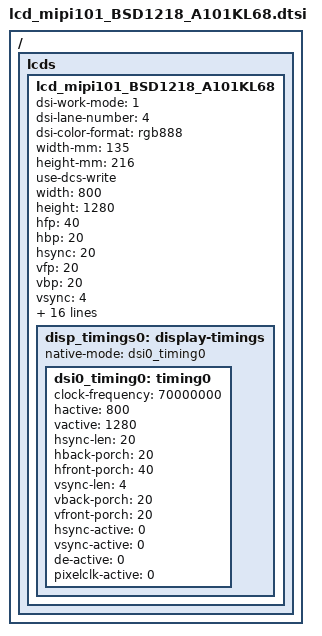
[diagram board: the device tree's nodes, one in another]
// SPDX-License-Identifier: GPL-2.0

/ {
	lcds: lcds  {
		lcd_mipi101_BSD1218_A101KL68: lcd_mipi101_BSD1218_A101KL68 {
			dsi-work-mode = <1>; /* video burst mode*/
			dsi-lane-number = <4>;
			dsi-color-format = "rgb888";
			width-mm = <135>;
			height-mm = <216>;
			use-dcs-write;

			/*mipi info*/
			width = <800>;
			height = <1280>;
			hfp = <40>;
			hbp = <20>;
			hsync = <20>;
			vfp = <20>;
			vbp = <20>;
			vsync = <4>;
			fps = <60>;
			work-mode = <0>;
			rgb-mode = <3>;
			lane-number = <4>;
			phy-freq = <550000>;
			phy-escape-clock = <52000>;/* kHz */
			phy-bit-clock = <550000000>; /* 550 MHz/lane, within the calculated range for 800x1280@60. */
			split-enable = <0>;
			eotp-enable = <0>;
			burst-mode = <2>;
			esd-check-enable = <0>;
			te-esd-en = <0>;

			/* DSI_CMD, DSI_MODE, timeout, len, cmd  */
			initial-command = [
				39 01 00 04 FF 98 81 03
				39 01 00 02 01 00
				39 01 00 02 02 00
				39 01 00 02 03 55
				39 01 00 02 04 55
				39 01 00 02 05 03 
				39 01 00 02 06 06 
				39 01 00 02 07 00 
				39 01 00 02 08 07 
				39 01 00 02 09 00 
				39 01 00 02 0a 00 
				39 01 00 02 0b 00 
				39 01 00 02 0c 00 
				39 01 00 02 0d 00 
				39 01 00 02 0e 00 
				39 01 00 02 0f 00 

				39 01 00 02 10 00 
				39 01 00 02 11 00 
				39 01 00 02 12 00
				39 01 00 02 13 00
				39 01 00 02 14 00
				39 01 00 02 15 00
				39 01 00 02 16 00
				39 01 00 02 17 00
				39 01 00 02 18 00
				39 01 00 02 19 00
				39 01 00 02 1a 00
				39 01 00 02 1b 00
				39 01 00 02 1c 00
				39 01 00 02 1d 00
				39 01 00 02 1e C0
				39 01 00 02 1f 80

				39 01 00 02 20 04
				39 01 00 02 21 03
				39 01 00 02 22 00
				39 01 00 02 23 00
                                39 01 00 02 24 00
				39 01 00 02 25 00
				39 01 00 02 26 00
				39 01 00 02 27 00
				39 01 00 02 28 33
				39 01 00 02 29 33
				39 01 00 02 2a 00
				39 01 00 02 2b 00
				39 01 00 02 2c 00
				39 01 00 02 2d 00
				39 01 00 02 2e 00
				39 01 00 02 2f 00

				39 01 00 02 30 00
				39 01 00 02 31 00
				39 01 00 02 32 00
				39 01 00 02 33 00
				39 01 00 02 34 04
				39 01 00 02 35 00
				39 01 00 02 36 00
				39 01 00 02 37 00
				39 01 00 02 38 3C
                                39 01 00 02 39 00
				39 01 00 02 3a 00
				39 01 00 02 3b 00
				39 01 00 02 3c 00
				39 01 00 02 3d 00
				39 01 00 02 3e 00
				39 01 00 02 3f 00

				39 01 00 02 40 00
				39 01 00 02 41 00
				39 01 00 02 42 00
				39 01 00 02 43 00
				39 01 00 02 44 00

				39 01 00 02 50 00
				39 01 00 02 51 11
				39 01 00 02 52 44
				39 01 00 02 53 55
				39 01 00 02 54 88
				39 01 00 02 55 AB
				39 01 00 02 56 00
				39 01 00 02 57 11
                                39 01 00 02 58 22
				39 01 00 02 59 33
				39 01 00 02 5a 44
				39 01 00 02 5b 55
				39 01 00 02 5c 66
				39 01 00 02 5d 77
				39 01 00 02 5e 00
				39 01 00 02 5f 02

				39 01 00 02 60 02
				39 01 00 02 61 0A
				39 01 00 02 62 09
				39 01 00 02 63 08
				39 01 00 02 64 13
				39 01 00 02 65 12
				39 01 00 02 66 11
				39 01 00 02 67 10
				39 01 00 02 68 0F
				39 01 00 02 69 0E
				39 01 00 02 6a 0D
				39 01 00 02 6b 0C
				39 01 00 02 6c 06
                                39 01 00 02 6d 07
				39 01 00 02 6e 02  
				39 01 00 02 6f 02

				39 01 00 02 70 02
				39 01 00 02 71 02
				39 01 00 02 72 02
				39 01 00 02 73 02 
				39 01 00 02 74 02
				39 01 00 02 75 02
				39 01 00 02 76 02  
				39 01 00 02 77 0A
				39 01 00 02 78 06
				39 01 00 02 79 07
				39 01 00 02 7a 10
				39 01 00 02 7b 11
				39 01 00 02 7c 12
				39 01 00 02 7d 13
				39 01 00 02 7e 0C
				39 01 00 02 7f 0D

				39 01 00 02 80 0E
                                39 01 00 02 81 0F
				39 01 00 02 82 09
				39 01 00 02 83 08
				39 01 00 02 84 02
				39 01 00 02 85 02
				39 01 00 02 86 02
				39 01 00 02 87 02
				39 01 00 02 88 02
				39 01 00 02 89 02
				39 01 00 02 8A 02

				39 01 00 04 FF 98 81 04
				39 01 00 02 6E 2A
				39 01 00 02 6F 37
				39 01 00 02 3A 24
				39 01 00 02 8D 19
				39 01 00 02 87 BA
				39 01 00 02 B2 D1
				39 01 00 02 88 0B
				39 01 00 02 38 01
				39 01 00 02 39 00
				39 01 00 02 B5 02
                                39 01 00 02 31 25
				39 01 00 02 3B 98
				39 01 00 04 FF 98 81 01

				39 01 00 02 22 0A
				39 01 00 02 31 0C
				39 01 00 02 53 40
				39 01 00 02 55 45
				39 01 00 02 50 B7
				39 01 00 02 51 B2
				39 01 00 02 60 07

				39 01 00 02 A0 22
				39 01 00 02 A1 3F
				39 01 00 02 A2 4E
				39 01 00 02 A3 17
				39 01 00 02 A4 1A
				39 01 00 02 A5 2D
				39 01 00 02 A6 21
				39 01 00 02 A7 22
				39 01 00 02 A8 C4
				39 01 00 02 A9 1B
                                39 01 00 02 AA 25
				39 01 00 02 AB A7
				39 01 00 02 AC 1A
				39 01 00 02 AD 19
				39 01 00 02 AE 4B
				39 01 00 02 AF 1F

				39 01 00 02 B0 2A
				39 01 00 02 B1 59
				39 01 00 02 B2 64
				39 01 00 02 B3 3F

				39 01 00 02 C0 22
				39 01 00 02 C1 48
				39 01 00 02 C2 59
				39 01 00 02 C3 15
				39 01 00 02 C4 15
				39 01 00 02 C5 28
				39 01 00 02 C6 1C
				39 01 00 02 C7 1E
				39 01 00 02 C8 C4
				39 01 00 02 C9 1C
				39 01 00 02 CA 2B
                                39 01 00 02 CB A3
				39 01 00 02 CC 1F
				39 01 00 02 CD 1E
				39 01 00 02 CE 52
				39 01 00 02 CF 24

				39 01 00 02 D0 2A
				39 01 00 02 D1 58
				39 01 00 02 D2 68
				39 01 00 02 D3 3F      
				39 01 00 04 FF 98 81 00
				05 01 78 01 11             //Delay 120ms
				05 01 14 01 29             //Delay 20ms
			];

			sleep-out-command = [
				39 01 00 04 FF 98 81 00        //page0
				05 01 14 01 28                //Delay 20ms
				05 01 78 01 10                //Delay 120ms
			];

			disp_timings0: display-timings {
				native-mode = <&dsi0_timing0>;
				dsi0_timing0: timing0 {
					clock-frequency = <70000000>;
					hactive = <800>;//<768>;
					vactive = <1280>;
					hsync-len = <20>;   //20, 50,10
					hback-porch = <20>; //50, 56,10
					hfront-porch = <40>;//50, 30,180
					vsync-len = <4>;//4
					vback-porch = <20>;//4
					vfront-porch = <20>;//8
					hsync-active = <0>;
					vsync-active = <0>;
					de-active = <0>;
					pixelclk-active = <0>;
				};
			};
		};
	};
};
